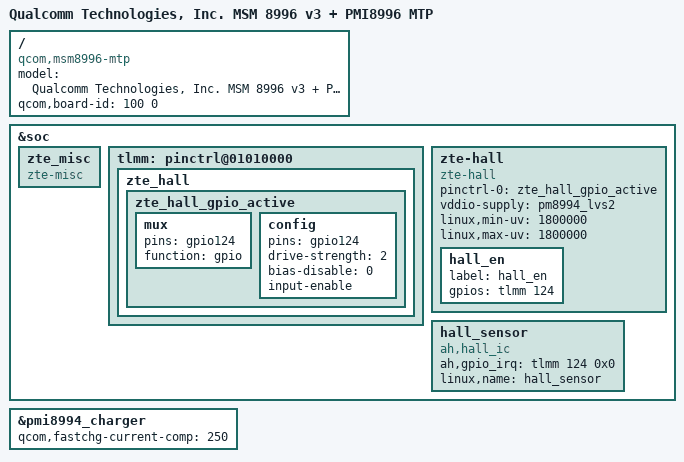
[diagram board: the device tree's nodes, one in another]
/* Copyright (c) 2015, The Linux Foundation. All rights reserved.
 *
 * This program is free software; you can redistribute it and/or modify
 * it under the terms of the GNU General Public License version 2 and
 * only version 2 as published by the Free Software Foundation.
 *
 * This program is distributed in the hope that it will be useful,
 * but WITHOUT ANY WARRANTY; without even the implied warranty of
 * MERCHANTABILITY or FITNESS FOR A PARTICULAR PURPOSE.  See the
 * GNU General Public License for more details.
 */


/dts-v1/;

#include "msm8996-v3.dtsi"
#include "msm-pmi8996.dtsi"
#include "msm8996-mtp.dtsi"

#include "zte-msm8996-v3-pmi8996-ailsa_ii.dtsi"

/ {
	model = "Qualcomm Technologies, Inc. MSM 8996 v3 + PMI8996 MTP";
	compatible = "qcom,msm8996-mtp", "qcom,msm8996", "qcom,mtp";
	qcom,board-id = <100 0>;
};
&soc {
	zte_misc {
		compatible = "zte-misc";
	};

	tlmm: pinctrl@01010000 {
		zte_hall: zte_hall {
			zte_hall_gpio_active: zte_hall_gpio_active {
				mux {
					pins = "gpio124";
					function = "gpio";
				};
				config {
					pins = "gpio124";
					drive-strength = <2>; /* 2 mA */
					bias-disable = <0>; /* no pull */
					input-enable; /* input */
				};
			};
		};
	};

	zte-hall {
		compatible = "zte-hall";
		pinctrl-names = "zte_hall_gpio_active";
		pinctrl-0 = <&zte_hall_gpio_active>;
		vddio-supply = <&pm8994_lvs2>;
		linux,min-uv = <1800000>;
		linux,max-uv = <1800000>;
		hall_en{
			label = "hall_en";
			gpios = <&tlmm 124 0x0>;
		};
	};

	hall_sensor {
		compatible = "ah,hall_ic";
		ah,gpio_irq = <&tlmm 124 0x0>;
		linux,name = "hall_sensor";
	};

};
&pmi8994_charger {
	qcom,fastchg-current-comp = <250>;
};
